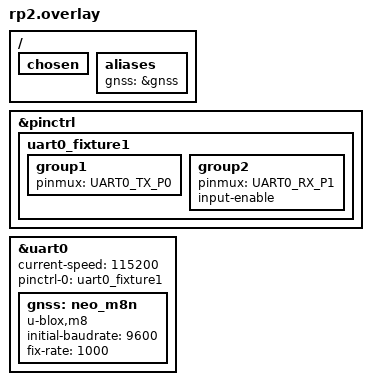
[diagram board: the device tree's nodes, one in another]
/* SPDX-License-Identifier: Apache-2.0 OR MIT */

/ {
	chosen {
		/delete-property/ zephyr,console;
		/delete-property/ zephyr,shell-uart;
	};

	aliases {
		gnss = &gnss;
	};
};

&pinctrl {
	uart0_fixture1: uart0_fixture1 {
		group1 {
			pinmux = <UART0_TX_P0>;
		};
		group2 {
			pinmux = <UART0_RX_P1>;
			input-enable;
		};
	};
};

/*
 * The fixture's crossed pair: the DUT's GP0 drives the harness's GP1 and
 * the harness's GP0 drives the DUT's GP1. The driver expects the receiver
 * at initial-baudrate on the wire, polls at current-speed first, and moves
 * the part up with CFG-PRT when that poll gets no answer.
 */
&uart0 {
	status = "okay";
	current-speed = <115200>;
	pinctrl-0 = <&uart0_fixture1>;
	pinctrl-names = "default";

	gnss: neo_m8n {
		compatible = "u-blox,m8";
		initial-baudrate = <9600>;
		fix-rate = <1000>;
		status = "okay";
	};
};
